VERSION "Powertrain_CAN_v1.0"

NS_ :

BS_:

BU_: VAL_SCENARIO_CTRL ENG_CTRL TCM CHS_GW DOMAIN_ROUTER Vector__XXX

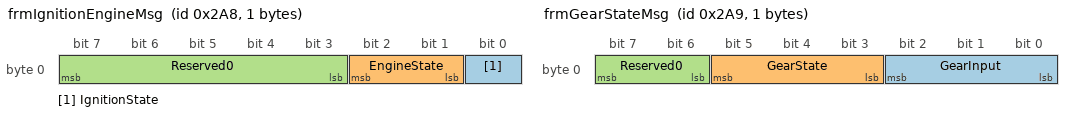
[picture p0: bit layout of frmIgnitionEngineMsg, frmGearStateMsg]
BO_ 680 frmIgnitionEngineMsg: 1 VAL_SCENARIO_CTRL
 SG_ IgnitionState  : 0|1@1+ (1,0) [0|1] "" ENG_CTRL
 SG_ EngineState    : 1|2@1+ (1,0) [0|3] "" ENG_CTRL
 SG_ Reserved0      : 3|5@1+ (1,0) [0|0] "" Vector__XXX

BO_ 681 frmGearStateMsg: 1 VAL_SCENARIO_CTRL
 SG_ GearInput      : 0|3@1+ (1,0) [0|7] "" TCM
 SG_ GearState      : 3|3@1+ (1,0) [0|7] "" TCM
 SG_ Reserved0      : 6|2@1+ (1,0) [0|0] "" Vector__XXX

BO_ 265 frmPowertrainGatewayMsg: 2 DOMAIN_ROUTER
 SG_ RoutingPolicy  : 0|8@1+ (1,0) [0|255] "" ENG_CTRL,TCM
 SG_ BoundaryStatus : 8|8@1+ (1,0) [0|255] "" ENG_CTRL,TCM

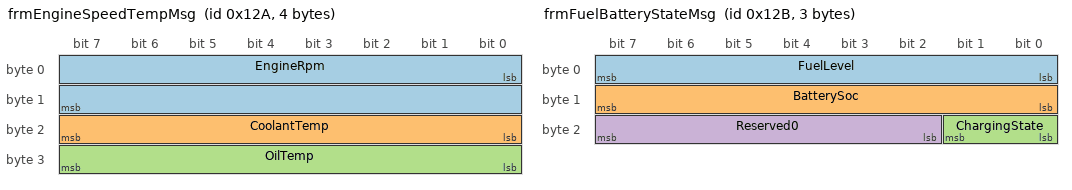
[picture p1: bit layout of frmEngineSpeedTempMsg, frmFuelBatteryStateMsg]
BO_ 298 frmEngineSpeedTempMsg: 4 ENG_CTRL
 SG_ EngineRpm       : 0|16@1+ (1,0) [0|65535] "rpm" TCM,DOMAIN_ROUTER
 SG_ CoolantTemp     : 16|8@1+ (1,0) [0|255] "degC" TCM,DOMAIN_ROUTER
 SG_ OilTemp         : 24|8@1+ (1,0) [0|255] "degC" TCM,DOMAIN_ROUTER

BO_ 299 frmFuelBatteryStateMsg: 3 ENG_CTRL
 SG_ FuelLevel       : 0|8@1+ (1,0) [0|100] "%" DOMAIN_ROUTER
 SG_ BatterySoc      : 8|8@1+ (1,0) [0|100] "%" DOMAIN_ROUTER
 SG_ ChargingState   : 16|2@1+ (1,0) [0|3] "" DOMAIN_ROUTER
 SG_ Reserved0       : 18|6@1+ (1,0) [0|0] "" Vector__XXX

BO_ 300 frmThrottleStateMsg: 2 ENG_CTRL
 SG_ ThrottlePos     : 0|8@1+ (1,0) [0|100] "%" TCM,DOMAIN_ROUTER
 SG_ ThrottleReq     : 8|8@1+ (1,0) [0|100] "%" TCM,DOMAIN_ROUTER

BO_ 301 frmTransmissionTempMsg: 2 TCM
 SG_ TransOilTemp    : 0|8@1+ (1,0) [0|255] "degC" ENG_CTRL,DOMAIN_ROUTER
 SG_ ClutchTemp      : 8|8@1+ (1,0) [0|255] "degC" ENG_CTRL,DOMAIN_ROUTER

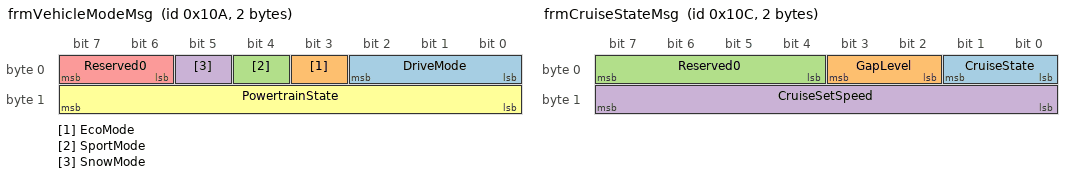
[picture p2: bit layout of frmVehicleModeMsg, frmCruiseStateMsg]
BO_ 266 frmVehicleModeMsg: 2 DOMAIN_ROUTER
 SG_ DriveMode       : 0|3@1+ (1,0) [0|7] "" ENG_CTRL,TCM
 SG_ EcoMode         : 3|1@1+ (1,0) [0|1] "" ENG_CTRL,TCM
 SG_ SportMode       : 4|1@1+ (1,0) [0|1] "" ENG_CTRL,TCM
 SG_ SnowMode        : 5|1@1+ (1,0) [0|1] "" ENG_CTRL,TCM
 SG_ Reserved0       : 6|2@1+ (1,0) [0|0] "" Vector__XXX
 SG_ PowertrainState : 8|8@1+ (1,0) [0|255] "" ENG_CTRL,TCM

BO_ 267 frmPowerLimitMsg: 2 DOMAIN_ROUTER
 SG_ TorqueLimit     : 0|8@1+ (1,0) [0|255] "Nm" ENG_CTRL,TCM
 SG_ SpeedLimit      : 8|8@1+ (1,0) [0|255] "km/h" ENG_CTRL,TCM

BO_ 268 frmCruiseStateMsg: 2 DOMAIN_ROUTER
 SG_ CruiseState     : 0|2@1+ (1,0) [0|3] "" ENG_CTRL,TCM
 SG_ GapLevel        : 2|2@1+ (1,0) [0|3] "" ENG_CTRL,TCM
 SG_ Reserved0       : 4|4@1+ (1,0) [0|0] "" Vector__XXX
 SG_ CruiseSetSpeed  : 8|8@1+ (1,0) [0|255] "km/h" ENG_CTRL,TCM

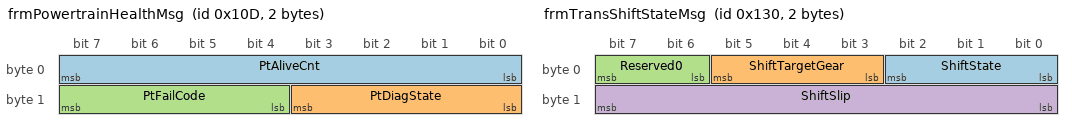
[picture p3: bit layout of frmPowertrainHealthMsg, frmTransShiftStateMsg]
BO_ 269 frmPowertrainHealthMsg: 2 DOMAIN_ROUTER
 SG_ PtAliveCnt      : 0|8@1+ (1,0) [0|255] "" VAL_SCENARIO_CTRL
 SG_ PtDiagState     : 8|4@1+ (1,0) [0|15] "" VAL_SCENARIO_CTRL
 SG_ PtFailCode      : 12|4@1+ (1,0) [0|15] "" VAL_SCENARIO_CTRL

BO_ 302 frmEngineTorqueMsg: 2 ENG_CTRL
 SG_ EngineTorqueAct : 0|16@1+ (1,0) [0|65535] "Nm" DOMAIN_ROUTER

BO_ 303 frmEngineLoadMsg: 1 ENG_CTRL
 SG_ EngineLoad      : 0|8@1+ (1,0) [0|100] "%" DOMAIN_ROUTER

BO_ 304 frmTransShiftStateMsg: 2 TCM
 SG_ ShiftState      : 0|3@1+ (1,0) [0|7] "" DOMAIN_ROUTER
 SG_ ShiftTargetGear : 3|3@1+ (1,0) [0|7] "" DOMAIN_ROUTER
 SG_ Reserved0       : 6|2@1+ (1,0) [0|0] "" Vector__XXX
 SG_ ShiftSlip       : 8|8@1+ (1,0) [0|255] "" DOMAIN_ROUTER

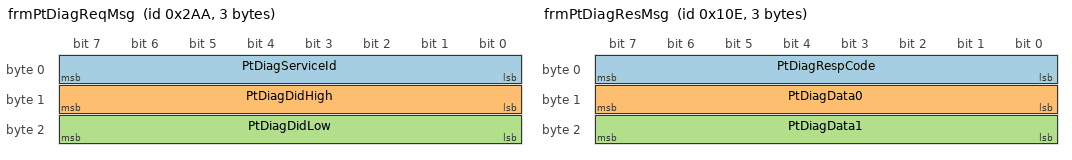
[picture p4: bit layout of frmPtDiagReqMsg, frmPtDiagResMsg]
BO_ 682 frmPtDiagReqMsg: 3 VAL_SCENARIO_CTRL
 SG_ PtDiagServiceId : 0|8@1+ (1,0) [0|255] "" DOMAIN_ROUTER
 SG_ PtDiagDidHigh   : 8|8@1+ (1,0) [0|255] "" DOMAIN_ROUTER
 SG_ PtDiagDidLow    : 16|8@1+ (1,0) [0|255] "" DOMAIN_ROUTER

BO_ 270 frmPtDiagResMsg: 3 DOMAIN_ROUTER
 SG_ PtDiagRespCode  : 0|8@1+ (1,0) [0|255] "" VAL_SCENARIO_CTRL
 SG_ PtDiagData0     : 8|8@1+ (1,0) [0|255] "" VAL_SCENARIO_CTRL
 SG_ PtDiagData1     : 16|8@1+ (1,0) [0|255] "" VAL_SCENARIO_CTRL

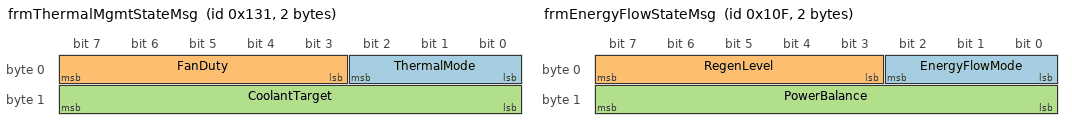
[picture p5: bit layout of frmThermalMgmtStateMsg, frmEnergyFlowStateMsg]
BO_ 305 frmThermalMgmtStateMsg: 2 ENG_CTRL
 SG_ ThermalMode     : 0|3@1+ (1,0) [0|7] "" DOMAIN_ROUTER
 SG_ FanDuty         : 3|5@1+ (1,0) [0|31] "" DOMAIN_ROUTER
 SG_ CoolantTarget   : 8|8@1+ (1,0) [0|255] "degC" DOMAIN_ROUTER

BO_ 271 frmEnergyFlowStateMsg: 2 DOMAIN_ROUTER
 SG_ EnergyFlowMode  : 0|3@1+ (1,0) [0|7] "" ENG_CTRL,TCM
 SG_ RegenLevel      : 3|5@1+ (1,0) [0|31] "" ENG_CTRL,TCM
 SG_ PowerBalance    : 8|8@1+ (1,0) [0|255] "" ENG_CTRL,TCM

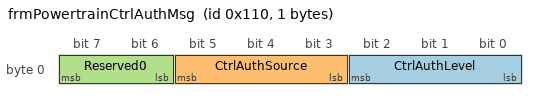
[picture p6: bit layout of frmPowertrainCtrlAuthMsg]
BO_ 272 frmPowertrainCtrlAuthMsg: 1 DOMAIN_ROUTER
 SG_ CtrlAuthLevel   : 0|3@1+ (1,0) [0|7] "" ENG_CTRL,TCM
 SG_ CtrlAuthSource  : 3|3@1+ (1,0) [0|7] "" ENG_CTRL,TCM
 SG_ Reserved0       : 6|2@1+ (1,0) [0|0] "" Vector__XXX

CM_ BO_ 680 "Powertrain baseline: ignition state and engine state.";
CM_ BO_ 681 "Powertrain baseline: gear input and gear state.";
CM_ BO_ 265 "Powertrain baseline: domain routing policy and boundary status.";
CM_ BO_ 298 "Powertrain baseline: engine RPM and thermal state.";
CM_ BO_ 299 "Powertrain baseline: fuel and battery state.";
CM_ BO_ 300 "Powertrain baseline: throttle position and request.";
CM_ BO_ 301 "Powertrain baseline: transmission thermal state.";
CM_ BO_ 266 "Powertrain baseline: drive mode and powertrain state.";
CM_ BO_ 267 "Powertrain baseline: torque and speed limits.";
CM_ BO_ 268 "Powertrain baseline: cruise state, gap, and set speed.";
CM_ BO_ 269 "Powertrain health/diagnostic state.";
CM_ BO_ 302 "Comm_204: engine torque extension.";
CM_ BO_ 303 "Comm_204: engine load extension.";
CM_ BO_ 304 "Comm_204: transmission shift state extension.";
CM_ BO_ 682 "Comm_205: powertrain diagnostic request.";
CM_ BO_ 270 "Comm_205: powertrain diagnostic response.";
CM_ BO_ 305 "Comm_204: thermal management state extension.";
CM_ BO_ 271 "Comm_204: energy flow state extension.";
CM_ BO_ 272 "Comm_204: powertrain control authorization extension.";

BA_DEF_ BO_ "GenMsgCycleTime" INT 0 10000;
BA_DEF_DEF_ "GenMsgCycleTime" 0;
BA_ "GenMsgCycleTime" BO_ 680 100;
BA_ "GenMsgCycleTime" BO_ 681 100;
BA_ "GenMsgCycleTime" BO_ 265 100;
BA_ "GenMsgCycleTime" BO_ 298 100;
BA_ "GenMsgCycleTime" BO_ 299 100;
BA_ "GenMsgCycleTime" BO_ 300 100;
BA_ "GenMsgCycleTime" BO_ 301 100;
BA_ "GenMsgCycleTime" BO_ 266 100;
BA_ "GenMsgCycleTime" BO_ 267 100;
BA_ "GenMsgCycleTime" BO_ 268 100;
BA_ "GenMsgCycleTime" BO_ 269 100;
BA_ "GenMsgCycleTime" BO_ 302 100;
BA_ "GenMsgCycleTime" BO_ 303 100;
BA_ "GenMsgCycleTime" BO_ 304 100;
BA_ "GenMsgCycleTime" BO_ 305 100;
BA_ "GenMsgCycleTime" BO_ 271 100;
BA_ "GenMsgCycleTime" BO_ 272 100;

  0 "Off"
  1 "On" ;

  0 "Off"
  1 "Starting"
  2 "Running"
  3 "Fault" ;

  0 "P"
  1 "R"
  2 "N"
  3 "D"
  4 "S"
  5 "M"
  6 "Reserved6"
  7 "Reserved7" ;

  0 "P"
  1 "R"
  2 "N"
  3 "D"
  4 "S"
  5 "M"
  6 "Reserved6"
  7 "Reserved7" ;

  0 "Idle"
  1 "Charging"
  2 "Discharging"
  3 "Fault" ;

  0 "Normal"
  1 "Eco"
  2 "Sport"
  3 "Snow"
  4 "Comfort"
  5 "Custom"
  6 "Reserved6"
  7 "Reserved7" ;

  0 "Off"
  1 "On" ;

  0 "Off"
  1 "On" ;

  0 "Off"
  1 "On" ;

  0 "Off"
  1 "Standby"
  2 "Active"
  3 "Fault" ;
